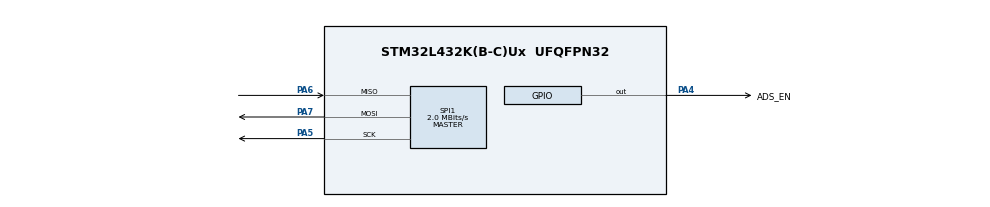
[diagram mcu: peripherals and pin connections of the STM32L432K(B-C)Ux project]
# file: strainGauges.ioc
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Mcu.Family=STM32L4
Mcu.Name=STM32L432K(B-C)Ux
Mcu.Package=UFQFPN32
NVIC.PriorityGroup=NVIC_PRIORITYGROUP_4
PA4.GPIO_Label=ADS_EN
PA4.PinState=GPIO_PIN_SET
PA4.Signal=GPIO_Output
PA5.Mode=Full_Duplex_Master
PA5.Signal=SPI1_SCK
PA6.Mode=Full_Duplex_Master
PA6.Signal=SPI1_MISO
PA7.Mode=Full_Duplex_Master
PA7.Signal=SPI1_MOSI
ProjectManager.HeapSize=0x200
ProjectManager.StackSize=0x400
ProjectManager.TargetToolchain=STM32CubeIDE
RCC.HSE_VALUE=8000000
RCC.HSI48_VALUE=48000000
RCC.HSI_VALUE=16000000
RCC.LSE_VALUE=32768
RCC.MSI_VALUE=4000000
RCC.VCOOutputFreq_Value=32000000
SPI1.CLKPhase=SPI_PHASE_2EDGE
SPI1.CalculateBaudRate=2.0 MBits/s
SPI1.DataSize=SPI_DATASIZE_8BIT
SPI1.Direction=SPI_DIRECTION_2LINES
SPI1.Mode=SPI_MODE_MASTER
SPI1.VirtualType=VM_MASTER
board=custom

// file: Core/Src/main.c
/* USER CODE BEGIN Header */
/**
  ******************************************************************************
  * @file           : main.c
  * @brief          : Main program body
  ******************************************************************************
  * @attention
  *
  * Copyright (c) 2025 STMicroelectronics.
  * All rights reserved.
  *
  * This software is licensed under terms that can be found in the LICENSE file
  * in the root directory of this software component.
  * If no LICENSE file comes with this software, it is provided AS-IS.
  *
  ******************************************************************************
  */
/* USER CODE END Header */
#include "main.h"
#include "spi.h"
#include "gpio.h"
#include "ads1118.h"

/* USER CODE BEGIN PV */
ADS ADS1118;
int status;
/* USER CODE END PV */

void SystemClock_Config(void);

int main(void)
{

  /* MCU Configuration--------------------------------------------------------*/

  /* Reset of all peripherals, Initializes the Flash interface and the Systick. */
  HAL_Init();

  /* Configure the system clock */
  SystemClock_Config();

  /* Initialize all configured peripherals */
  MX_GPIO_Init();
  MX_SPI1_Init();

  /* Infinite loop */
  while (1)
  {

  }
}

void SystemClock_Config(void)
{
  RCC_OscInitTypeDef RCC_OscInitStruct = {0};
  RCC_ClkInitTypeDef RCC_ClkInitStruct = {0};

  /** Configure the main internal regulator output voltage
  */
  if (HAL_PWREx_ControlVoltageScaling(PWR_REGULATOR_VOLTAGE_SCALE1) != HAL_OK)
  {
    Error_Handler();
  }

  /** Initializes the RCC Oscillators according to the specified parameters
  * in the RCC_OscInitTypeDef structure.
  */
  RCC_OscInitStruct.OscillatorType = RCC_OSCILLATORTYPE_MSI;
  RCC_OscInitStruct.MSIState = RCC_MSI_ON;
  RCC_OscInitStruct.MSICalibrationValue = 0;
  RCC_OscInitStruct.MSIClockRange = RCC_MSIRANGE_6;
  RCC_OscInitStruct.PLL.PLLState = RCC_PLL_NONE;
  if (HAL_RCC_OscConfig(&RCC_OscInitStruct) != HAL_OK)
  {
    Error_Handler();
  }

  /** Initializes the CPU, AHB and APB buses clocks
  */
  RCC_ClkInitStruct.ClockType = RCC_CLOCKTYPE_HCLK|RCC_CLOCKTYPE_SYSCLK
                              |RCC_CLOCKTYPE_PCLK1|RCC_CLOCKTYPE_PCLK2;
  RCC_ClkInitStruct.SYSCLKSource = RCC_SYSCLKSOURCE_MSI;
  RCC_ClkInitStruct.AHBCLKDivider = RCC_SYSCLK_DIV1;
  RCC_ClkInitStruct.APB1CLKDivider = RCC_HCLK_DIV1;
  RCC_ClkInitStruct.APB2CLKDivider = RCC_HCLK_DIV1;

  if (HAL_RCC_ClockConfig(&RCC_ClkInitStruct, FLASH_LATENCY_0) != HAL_OK)
  {
    Error_Handler();
  }
}

void Error_Handler(void)
{
  __disable_irq();
  while (1)
  {
  }
}
